# PIC32CM2532LS00064 device description
Architecture: CORTEX-M23; Family: PIC32CM; Series: PIC32CMLS00
Registers are 32-bit, read-write, reset 0x0 unless marked. A register's access mark holds for its fields unless they carry their own. Offsets are from the block's base; [hi:lo] are bit positions; {n}, {i} and the like mark numbered series.

## OTP1_FUSES — Non-Volatile Fuses
Instances: OTP1_FUSES 0x00806000 in fuses
0x00 OTP1_WORD_0 ro reset not defined — OTP1 Page Word 0
  [10] BOOTROM_SECEN — Security Enable Fuse
0x04 OTP1_WORD_1 ro reset not defined — OTP1 Page Word 1
  [31:0] BOOTROM_NVMCRC — CRC for NVM DWORD

## OTP2_FUSES — Non-Volatile Fuses
Instances: OTP2_FUSES 0x00806008 in fuses
0x04 OTP2_WORD_1 ro reset not defined — OTP2 Page Word 1
  [15] PM_NVM3VSWDIS — 3V NVM switch disable

## SW_CALIB_FUSES — Non-Volatile Fuses
Instances: SW_CALIB_FUSES 0x00806020 in fuses
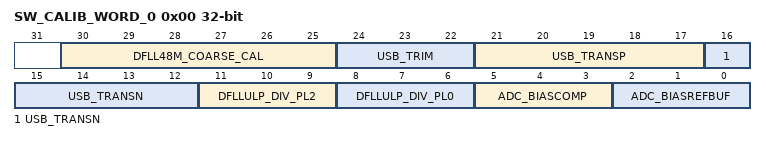
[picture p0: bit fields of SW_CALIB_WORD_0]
0x00 SW_CALIB_WORD_0 ro reset not defined — SW_CALIB Page Word 0
  [30:25] DFLL48M_COARSE_CAL — DFLL48M Coarse Calibration
  [24:22] USB_TRIM — USB pad Trim calibration
  [21:17] USB_TRANSP — USB pad Transp calibration
  [16:12] USB_TRANSN — USB pad Transn calibration
  [11:9] DFLLULP_DIV_PL2 — DFLLULP DIV at PL2
  [8:6] DFLLULP_DIV_PL0 — DFLLULP DIV at PL0
  [5:3] ADC_BIASCOMP — ADC Comparator Scaling
  [2:0] ADC_BIASREFBUF — ADC Bias Reference Buffer Scaling

## USER_FUSES — Non-Volatile Fuses
Instances: USER_FUSES 0x00804000 in fuses
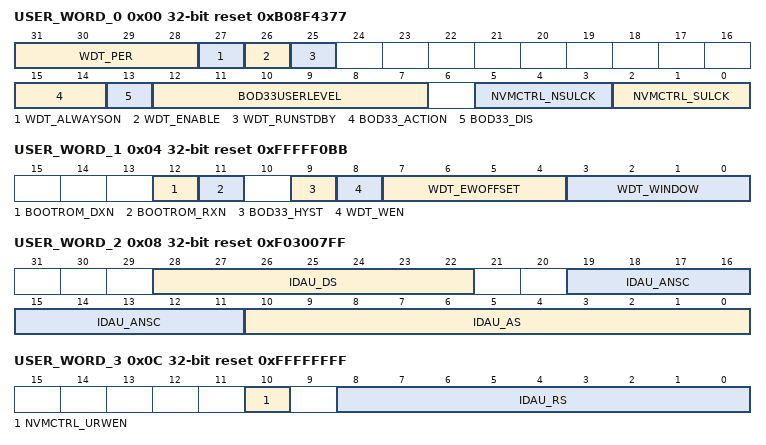
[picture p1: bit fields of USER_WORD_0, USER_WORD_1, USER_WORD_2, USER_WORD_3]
0x00 USER_WORD_0 reset 0xB08F4377 — USER Page Word 0
  [31:28] WDT_PER — WDT Period
  [27] WDT_ALWAYSON
  [26] WDT_ENABLE
  [25] WDT_RUNSTDBY — WDT Run During Standby
  [15:14] BOD33_ACTION
  [13] BOD33_DIS — BOD33 Disable
  [12:7] BOD33USERLEVEL
  [5:3] NVMCTRL_NSULCK — NVM Non-Secure Region Locks
  [2:0] NVMCTRL_SULCK — NVM Secure Region Locks
0x04 USER_WORD_1 reset 0xFFFFF0BB — USER Page Word 1
  [12] BOOTROM_DXN — DATA FLASH is eXecute Never
  [11] BOOTROM_RXN — RAM is eXecute Never
  [9] BOD33_HYST — BOD33 Hysteresis
  [8] WDT_WEN — WDT Window Mode Enable
  [7:4] WDT_EWOFFSET — WDT Early Warning Offset
  [3:0] WDT_WINDOW
0x08 USER_WORD_2 reset 0xF03007FF — USER Page Word 2
  [28:22] IDAU_DS — Data Secure
  [19:11] IDAU_ANSC — Application Non-Secure Callable
  [10:0] IDAU_AS — Application Secure
0x0C USER_WORD_3 reset 0xFFFFFFFF — USER Page Word 3
  [10] NVMCTRL_URWEN — User Row Write Enable
  [8:0] IDAU_RS — RAM Secure
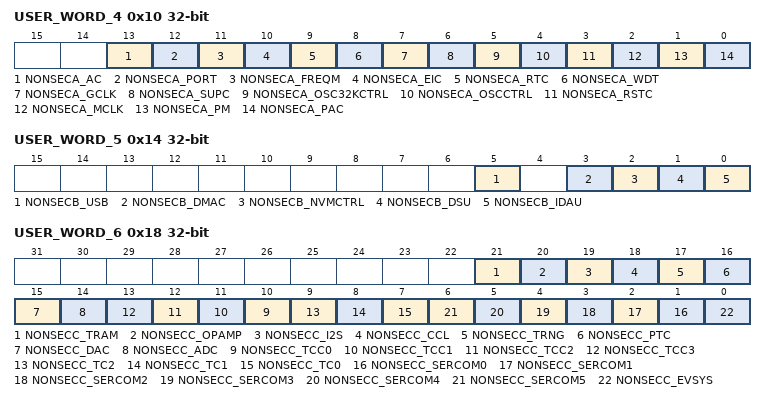
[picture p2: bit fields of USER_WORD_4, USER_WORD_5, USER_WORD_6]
0x10 USER_WORD_4 — USER Page Word 4
  [13] NONSECA_AC — AC Non-Secure
  [12] NONSECA_PORT — PORT Non-Secure
  [11] NONSECA_FREQM — FREQM Non-Secure
  [10] NONSECA_EIC — EIC Non-Secure
  [9] NONSECA_RTC — RTC Non-Secure
  [8] NONSECA_WDT — WDT Non-Secure
  [7] NONSECA_GCLK — GCLK Non-Secure
  [6] NONSECA_SUPC — SUPC Non-Secure
  [5] NONSECA_OSC32KCTRL — OSC32KCTRL Non-Secure
  [4] NONSECA_OSCCTRL — OSCCTRL Non-Secure
  [3] NONSECA_RSTC — RSTC Non-Secure
  [2] NONSECA_MCLK — MCLK Non-Secure
  [1] NONSECA_PM — PM Non-Secure
  [0] NONSECA_PAC — PAC Non-Secure
0x14 USER_WORD_5 — USER Page Word 5
  [5] NONSECB_USB — USB Non-Secure
  [3] NONSECB_DMAC — DMAC Non-Secure
  [2] NONSECB_NVMCTRL — NVMCTRL Non-Secure
  [1] NONSECB_DSU — DSU Non-Secure
  [0] NONSECB_IDAU — IDAU Non-Secure
0x18 USER_WORD_6 — USER Page Word 6
  [21] NONSECC_TRAM — TRAM Non-Secure
  [20] NONSECC_OPAMP — OPAMP Non-Secure
  [19] NONSECC_I2S — I2S Non-Secure
  [18] NONSECC_CCL — CCL Non-Secure
  [17] NONSECC_TRNG — TRNG Non-Secure
  [16] NONSECC_PTC — PTC Non-Secure
  [15] NONSECC_DAC — DAC Non-Secure
  [14] NONSECC_ADC — ADC Non-Secure
  [n+10] NONSECC_TCC{n} (n=0..3) — TCC{n} Non-Secure
  [9] NONSECC_TC2 — TC2 Non-Secure
  [8] NONSECC_TC1 — TC1 Non-Secure
  [7] NONSECC_TC0 — TC0 Non-Secure
  [n+1] NONSECC_SERCOM{n} (n=0..5) — SERCOM{n} Non-Secure
  [0] NONSECC_EVSYS — EVSYS Non-Secure
0x1C USER_WORD_7 — USER Page Word 7
  [31:0] BOOTROM_CDIROFFSET — Location of CDI value when DICE is programmed
0x20 USER_WORD_8 reset 0xE87673B6 — USER Page Word 8
  [31:0] BOOTROM_USERCRC — CRC for USER[1,2,3] DWORDS

## Notices in the file
Copyright (c) 2019 Microchip Technology Inc.
SPDX-License-Identifier: Apache-2.0
Licensed under the Apache License, Version 2.0 (the "License");
you may not use this file except in compliance with the License.
You may obtain a copy of the License at
http://www.apache.org/licenses/LICENSE-2.0
Unless required by applicable law or agreed to in writing, software
distributed under the License is distributed on an "AS IS" BASIS,
WITHOUT WARRANTIES OR CONDITIONS OF ANY KIND, either express or implied.
See the License for the specific language governing permissions and
limitations under the License.
